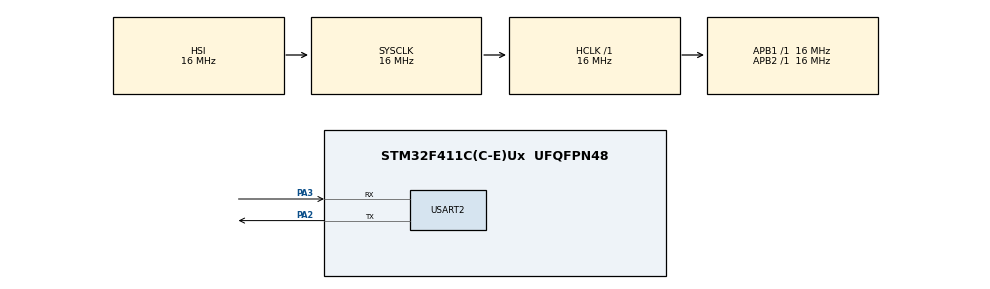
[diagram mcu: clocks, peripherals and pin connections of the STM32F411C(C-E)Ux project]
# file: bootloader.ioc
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Mcu.Family=STM32F4
Mcu.Name=STM32F411C(C-E)Ux
Mcu.Package=UFQFPN48
NVIC.PriorityGroup=NVIC_PRIORITYGROUP_4
PA2.Mode=Asynchronous
PA2.Signal=USART2_TX
PA3.Mode=Asynchronous
PA3.Signal=USART2_RX
ProjectManager.HeapSize=0x200
ProjectManager.StackSize=0x400
ProjectManager.TargetToolchain=Makefile
RCC.AHBFreq_Value=16000000
RCC.APB1Freq_Value=16000000
RCC.APB2Freq_Value=16000000
RCC.CortexFreq_Value=16000000
RCC.HSE_VALUE=25000000
RCC.HSI_VALUE=16000000
RCC.LSE_VALUE=32768
RCC.SYSCLKFreq_VALUE=16000000
RCC.VCOOutputFreq_Value=192000000
USART2.VirtualMode=VM_ASYNC
board=custom

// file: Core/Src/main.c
/* USER CODE BEGIN Header */
/**
  ******************************************************************************
  * @file           : main.c
  * @brief          : Main program body
  ******************************************************************************
  * @attention
  *
  * Copyright (c) 2024 STMicroelectronics.
  * All rights reserved.
  *
  * This software is licensed under terms that can be found in the LICENSE file
  * in the root directory of this software component.
  * If no LICENSE file comes with this software, it is provided AS-IS.
  *
  ******************************************************************************
  */
/* USER CODE END Header */
#include "main.h"
#include "usart.h"
#include "gpio.h"

/* USER CODE BEGIN Includes */
#include "stdio.h"
/* USER CODE END Includes */

/* USER CODE BEGIN PM */
typedef void (*pFunction)(void);
/* USER CODE END PM */

/* USER CODE BEGIN PV */
#define FLASH_APP_ADDR     0x8008000

#define BOOT_SIGNATURE      0xB00720AD  // "BOOTLOAD" signature in RAM
#define APP_SIGNATURE      0xB00720AA  // "APP" signature in RAM
#define RAM_SIGNATURE_ADDR  ((volatile uint32_t*)0x2001FFF0)  // Adjust to your system's RAM base address
/* USER CODE END PV */

void SystemClock_Config(void);
/* USER CODE BEGIN PFP */
void go2APP(void);
void* Boot_GetApplicationAddress(void);
int is_application_valid(void);
/* USER CODE END PFP */

/* USER CODE BEGIN 0 */
void* Boot_GetApplicationAddress(void) {
    // Check for bootloader signature in non-initialized RAM
    if (*RAM_SIGNATURE_ADDR != APP_SIGNATURE) {
        // Do not clear the signature here, as it might need to restart the bootloader
        return NULL;  // Bootloader should start
    }

    // Check application integrity (simple check for now, you can expand this)
    if (is_application_valid()) {
        return (void*)FLASH_APP_ADDR;  // Return application base address if valid
    }

    return NULL;  // Application is not valid, start bootloader
}

int is_application_valid(void) {
    // You can implement an actual CRC or checksum validation here
    // For simplicity, assume application is valid if vector table's first entry is a valid stack pointer
    uint32_t sp = *(volatile uint32_t*)FLASH_APP_ADDR;
    return 1;
    return (sp >= 0x20000000 && sp <= 0x20010000);  // Check if SP is within valid RAM range
    //  if(((*(uint32_t*) FLASH_APP_ADDR) & 0x2FFE0000) == 0x20020000)
    //  {
    //	  printf("APP starts...\r\n");
    //  } else
    //  {
    //    printf("No APP founddddd.\r\n");
    //  }
}

void go2APP(void)
{
	uint32_t JumpAddress;
	pFunction Jump_To_Application;

	//jump to the application
	JumpAddress = *(uint32_t *) (FLASH_APP_ADDR + 4);
	Jump_To_Application = (pFunction) JumpAddress;
	//init application's stack pointer
	__set_MSP(*(uint32_t *)FLASH_APP_ADDR);

	__DSB();  // Data Synchronization Barrier
	__ISB();  // Instruction Synchronization Barrier

	Jump_To_Application();
}

int _write(int file, char *ptr, int len)
{
	int DataIdx;

	for (DataIdx=0; DataIdx < len; DataIdx++)
	{
		HAL_UART_Transmit(&huart2, (uint8_t *) ptr++, 1, 100);
	}
	return len;
}
/* USER CODE END 0 */

int main(void)
{

  /* MCU Configuration--------------------------------------------------------*/

  /* Reset of all peripherals, Initializes the Flash interface and the Systick. */
  HAL_Init();

  /* Configure the system clock */
  SystemClock_Config();

  /* Initialize all configured peripherals */
  MX_GPIO_Init();
  MX_USART2_UART_Init();
  /* USER CODE BEGIN 2 */
  printf("Bootloader start\r\n");

  printf("Reseting... \r\n");
  HAL_Delay(5000);
  *RAM_SIGNATURE_ADDR = APP_SIGNATURE;  // Clear the bootloader signature in RAM

  NVIC_SystemReset();       // Trigger a system reset to start the application
  /* USER CODE END 2 */

  /* Infinite loop */
  while (1)
  {

  }
}

void SystemClock_Config(void)
{
  RCC_OscInitTypeDef RCC_OscInitStruct = {0};
  RCC_ClkInitTypeDef RCC_ClkInitStruct = {0};

  /** Configure the main internal regulator output voltage
  */
  __HAL_RCC_PWR_CLK_ENABLE();
  __HAL_PWR_VOLTAGESCALING_CONFIG(PWR_REGULATOR_VOLTAGE_SCALE1);

  /** Initializes the RCC Oscillators according to the specified parameters
  * in the RCC_OscInitTypeDef structure.
  */
  RCC_OscInitStruct.OscillatorType = RCC_OSCILLATORTYPE_HSI;
  RCC_OscInitStruct.HSIState = RCC_HSI_ON;
  RCC_OscInitStruct.HSICalibrationValue = RCC_HSICALIBRATION_DEFAULT;
  RCC_OscInitStruct.PLL.PLLState = RCC_PLL_NONE;
  if (HAL_RCC_OscConfig(&RCC_OscInitStruct) != HAL_OK)
  {
    Error_Handler();
  }

  /** Initializes the CPU, AHB and APB buses clocks
  */
  RCC_ClkInitStruct.ClockType = RCC_CLOCKTYPE_HCLK|RCC_CLOCKTYPE_SYSCLK
                              |RCC_CLOCKTYPE_PCLK1|RCC_CLOCKTYPE_PCLK2;
  RCC_ClkInitStruct.SYSCLKSource = RCC_SYSCLKSOURCE_HSI;
  RCC_ClkInitStruct.AHBCLKDivider = RCC_SYSCLK_DIV1;
  RCC_ClkInitStruct.APB1CLKDivider = RCC_HCLK_DIV1;
  RCC_ClkInitStruct.APB2CLKDivider = RCC_HCLK_DIV1;

  if (HAL_RCC_ClockConfig(&RCC_ClkInitStruct, FLASH_LATENCY_0) != HAL_OK)
  {
    Error_Handler();
  }
}

void Error_Handler(void)
{
  __disable_irq();
  while (1)
  {
  }
}
